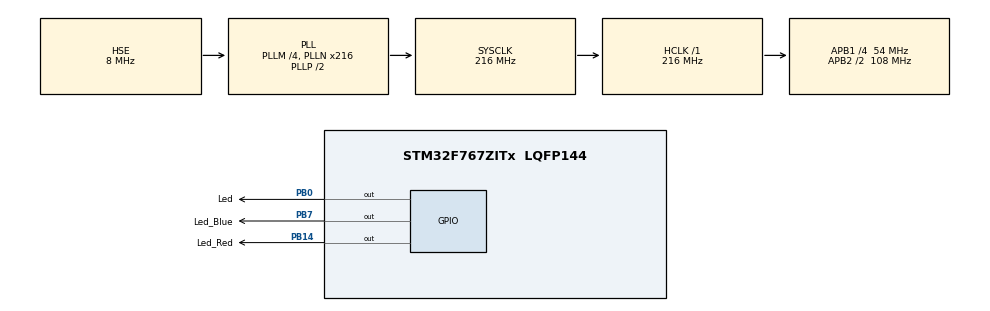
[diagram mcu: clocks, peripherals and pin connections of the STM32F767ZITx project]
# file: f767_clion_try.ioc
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FREERTOS.Tasks01=MainTask,24,128,StartMainTask,Default,NULL,Dynamic,NULL,NULL;SecondTask,24,128,StartSecondTask,Default,NULL,Dynamic,NULL,NULL
FREERTOS.configUSE_NEWLIB_REENTRANT=1
Mcu.Family=STM32F7
Mcu.Name=STM32F767ZITx
Mcu.Package=LQFP144
NVIC.PriorityGroup=NVIC_PRIORITYGROUP_4
NVIC.TIM8_TRG_COM_TIM14_IRQn=true\:15\:0\:false\:false\:true\:false\:false\:true
NVIC.TimeBase=TIM8_TRG_COM_TIM14_IRQn
NVIC.TimeBaseIP=TIM14
PA13.Mode=Trace_Asynchronous_SW
PA13.Signal=SYS_JTMS-SWDIO
PA14.Mode=Trace_Asynchronous_SW
PA14.Signal=SYS_JTCK-SWCLK
PB0.GPIO_Label=Led
PB0.Signal=GPIO_Output
PB14.GPIO_Label=Led_Red
PB14.Signal=GPIO_Output
PB3.Mode=Trace_Asynchronous_SW
PB3.Signal=SYS_JTDO-SWO
PB7.GPIO_Label=Led_Blue
PB7.Signal=GPIO_Output
PH0/OSC_IN.Mode=HSE-External-Oscillator
PH0/OSC_IN.Signal=RCC_OSC_IN
PH1/OSC_OUT.Mode=HSE-External-Oscillator
PH1/OSC_OUT.Signal=RCC_OSC_OUT
ProjectManager.HeapSize=0x200
ProjectManager.StackSize=0x400
ProjectManager.TargetToolchain=STM32CubeIDE
RCC.48MHZClocksFreq_Value=24000000
RCC.AHBFreq_Value=216000000
RCC.APB1CLKDivider=RCC_HCLK_DIV4
RCC.APB1Freq_Value=54000000
RCC.APB1TimFreq_Value=108000000
RCC.APB2CLKDivider=RCC_HCLK_DIV2
RCC.APB2Freq_Value=108000000
RCC.APB2TimFreq_Value=216000000
RCC.CortexFreq_Value=216000000
RCC.HCLKFreq_Value=216000000
RCC.HSE_VALUE=8000000
RCC.HSI_VALUE=16000000
RCC.PLLM=4
RCC.PLLMUL=RCC_PLL_MUL9
RCC.PLLN=216
RCC.PLLQ=4
RCC.PLLSourceVirtual=RCC_PLLSOURCE_HSE
RCC.PRESCALERUSB=RCC_USBCLKSOURCE_PLL_DIV1_5
RCC.SYSCLKFreq_VALUE=216000000
RCC.SYSCLKSource=RCC_SYSCLKSOURCE_PLLCLK
RCC.SYSCLKSourceVirtual=RCC_SYSCLKSOURCE_PLLCLK
RCC.USBFreq_Value=108000000
RCC.VCOOutputFreq_Value=432000000
VP_FREERTOS_VS_CMSIS_V2.Mode=CMSIS_V2
VP_SYS_VS_tim14.Mode=TIM14
board=NUCLEO-F767ZI

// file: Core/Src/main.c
/* USER CODE BEGIN Header */
/**
  ******************************************************************************
  * @file           : main.c
  * @brief          : Main program body
  ******************************************************************************
  * @attention
  *
  * <h2><center>&copy; Copyright (c) 2021 STMicroelectronics.
  * All rights reserved.</center></h2>
  *
  * This software component is licensed by ST under BSD 3-Clause license,
  * the "License"; You may not use this file except in compliance with the
  * License. You may obtain a copy of the License at:
  *                        opensource.org/licenses/BSD-3-Clause
  *
  ******************************************************************************
  */
/* USER CODE END Header */
#include "main.h"
#include "cmsis_os.h"

/* USER CODE BEGIN Includes */
#include <assert.h>
//from github, testing fetch/merge
#include "some_lib.h"

/* USER CODE END Includes */

/* Definitions for MainTask */
osThreadId_t MainTaskHandle;
const osThreadAttr_t MainTask_attributes = {
  .name = "MainTask",
  .stack_size = 128 * 4,
  .priority = (osPriority_t) osPriorityNormal,
};
/* Definitions for SecondTask */
osThreadId_t SecondTaskHandle;
const osThreadAttr_t SecondTask_attributes = {
  .name = "SecondTask",
  .stack_size = 128 * 4,
  .priority = (osPriority_t) osPriorityNormal,
};

void SystemClock_Config(void);
static void MX_GPIO_Init(void);
void StartMainTask(void *argument);
void StartSecondTask(void *argument);

/* USER CODE BEGIN PFP */
void main_thread(void);

/* USER CODE END PFP */

/* USER CODE BEGIN 0 */
static_assert(sizeof(int) % 4 == 0, "error");

/* USER CODE END 0 */

int main(void)
{

  /* MCU Configuration--------------------------------------------------------*/

  /* Reset of all peripherals, Initializes the Flash interface and the Systick. */
  HAL_Init();

  /* Configure the system clock */
  SystemClock_Config();

  /* Initialize all configured peripherals */
  MX_GPIO_Init();

  /* Init scheduler */
  osKernelInitialize();

  /* Create the thread(s) */
  /* creation of MainTask */
  MainTaskHandle = osThreadNew(StartMainTask, NULL, &MainTask_attributes);

  /* creation of SecondTask */
  SecondTaskHandle = osThreadNew(StartSecondTask, NULL, &SecondTask_attributes);

  /* Start scheduler */
  osKernelStart();

  /* We should never get here as control is now taken by the scheduler */
  /* Infinite loop */
  while (1)
  {

    /* USER CODE BEGIN 3 */
    /* We shouldn't get here */
    NVIC_SystemReset();

  }
  /* USER CODE END 3 */
}

void SystemClock_Config(void)
{
  RCC_OscInitTypeDef RCC_OscInitStruct = {0};
  RCC_ClkInitTypeDef RCC_ClkInitStruct = {0};

  /** Configure the main internal regulator output voltage
  */
  __HAL_RCC_PWR_CLK_ENABLE();
  __HAL_PWR_VOLTAGESCALING_CONFIG(PWR_REGULATOR_VOLTAGE_SCALE1);
  /** Initializes the RCC Oscillators according to the specified parameters
  * in the RCC_OscInitTypeDef structure.
  */
  RCC_OscInitStruct.OscillatorType = RCC_OSCILLATORTYPE_HSE;
  RCC_OscInitStruct.HSEState = RCC_HSE_ON;
  RCC_OscInitStruct.PLL.PLLState = RCC_PLL_ON;
  RCC_OscInitStruct.PLL.PLLSource = RCC_PLLSOURCE_HSE;
  RCC_OscInitStruct.PLL.PLLM = 4;
  RCC_OscInitStruct.PLL.PLLN = 216;
  RCC_OscInitStruct.PLL.PLLP = RCC_PLLP_DIV2;
  RCC_OscInitStruct.PLL.PLLQ = 4;
  RCC_OscInitStruct.PLL.PLLR = 2;
  if (HAL_RCC_OscConfig(&RCC_OscInitStruct) != HAL_OK)
  {
    Error_Handler();
  }
  /** Activate the Over-Drive mode
  */
  if (HAL_PWREx_EnableOverDrive() != HAL_OK)
  {
    Error_Handler();
  }
  /** Initializes the CPU, AHB and APB buses clocks
  */
  RCC_ClkInitStruct.ClockType = RCC_CLOCKTYPE_HCLK|RCC_CLOCKTYPE_SYSCLK
                              |RCC_CLOCKTYPE_PCLK1|RCC_CLOCKTYPE_PCLK2;
  RCC_ClkInitStruct.SYSCLKSource = RCC_SYSCLKSOURCE_PLLCLK;
  RCC_ClkInitStruct.AHBCLKDivider = RCC_SYSCLK_DIV1;
  RCC_ClkInitStruct.APB1CLKDivider = RCC_HCLK_DIV4;
  RCC_ClkInitStruct.APB2CLKDivider = RCC_HCLK_DIV2;

  if (HAL_RCC_ClockConfig(&RCC_ClkInitStruct, FLASH_LATENCY_7) != HAL_OK)
  {
    Error_Handler();
  }
}

static void MX_GPIO_Init(void)
{
  GPIO_InitTypeDef GPIO_InitStruct = {0};

  /* GPIO Ports Clock Enable */
  __HAL_RCC_GPIOH_CLK_ENABLE();
  __HAL_RCC_GPIOB_CLK_ENABLE();
  __HAL_RCC_GPIOA_CLK_ENABLE();

  /*Configure GPIO pin Output Level */
  HAL_GPIO_WritePin(GPIOB, Led_Pin|Led_Red_Pin|Led_Blue_Pin, GPIO_PIN_RESET);

  /*Configure GPIO pins : Led_Pin Led_Red_Pin Led_Blue_Pin */
  GPIO_InitStruct.Pin = Led_Pin|Led_Red_Pin|Led_Blue_Pin;
  GPIO_InitStruct.Mode = GPIO_MODE_OUTPUT_PP;
  GPIO_InitStruct.Pull = GPIO_NOPULL;
  GPIO_InitStruct.Speed = GPIO_SPEED_FREQ_LOW;
  HAL_GPIO_Init(GPIOB, &GPIO_InitStruct);

}

void StartMainTask(void *argument) {
  /* USER CODE BEGIN 5 */
  /* C++ */
    main_thread();
  /* Infinite loop */
  for(;;) {

  }
  /* USER CODE END 5 */
}

void StartSecondTask(void *argument)
{
  /* USER CODE BEGIN StartSecondTask */
  /* Infinite loop */
  for(;;)
  {
      HAL_GPIO_TogglePin(Led_Red_GPIO_Port, Led_Red_Pin);
      osDelay(300);
  }
  /* USER CODE END StartSecondTask */
}

void HAL_TIM_PeriodElapsedCallback(TIM_HandleTypeDef *htim)
{
  if (htim->Instance == TIM14) {
    HAL_IncTick();
  }
}

void Error_Handler(void)
{
  __disable_irq();
  while (1)
  {
  }
}

/************************ (C) COPYRIGHT STMicroelectronics *****END OF FILE****/
